# nrf54h20_engb_application register map
Vendor: Nordic Semiconductor; Series: nRF54h; File version: 1
CPU: CM33 r0p4, little endian, MPU, FPU, 3 interrupt priority bits, 480 interrupts, 8 SAU regions
Registers are 32-bit, read-write, reset 0x0 unless marked. A register's access mark holds for its fields unless they carry their own. Offsets are from the block's base; [hi:lo] are bit positions; lines under a group give offsets from that group; {n}, {i} and the like mark numbered series; 'fields as' and 'values as' point back to an identical list.

## GLOBAL_I3CCORE120_NS (part 2 of 2) — I3CCORE 0
Base 0x2FBE0000
Same registers: GLOBAL_I3CCORE121_NS 0x2FBE1000
0x900 DMA group — Unspecified
  0x00 CH0 group — Unspecified
    0x00 SAR0 — This register contains the source address of the DMA transfer.
      [31:0] SAR — Current Source Address of DMA transfer.
    0x08 DAR0 — This register contains the destination address of the DMA transfer.
      [31:0] DAR — Current Destination address of DMA transfer.
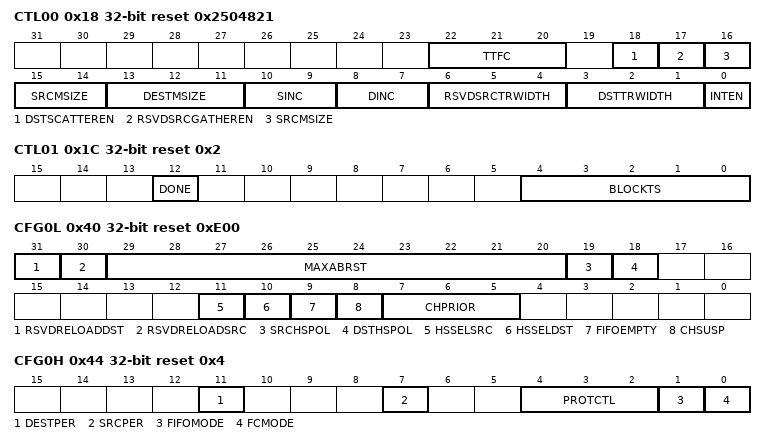
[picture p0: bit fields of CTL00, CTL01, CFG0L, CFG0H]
    0x18 CTL00 reset 0x2504821 — This register contains fields that control the DMA transfer.
      [22:20] TTFC — Transfer Type and Flow Control.
        {v}=TT_FC_{v} (Unspecified) (v=0..7)
      [18] DSTSCATTEREN — Destination scatter enable.
        0=DST_SCATTER_DISABLE (Unspecified); 1=DST_SCATTER_ENABLE (Unspecified)
      [17] RSVDSRCGATHEREN ro — Reserved field - read-only
      [16:14] SRCMSIZE — Source Burst Transaction Length.
        {v}=SRC_MSIZE_{v} (Unspecified) (v=0..7)
      [13:11] DESTMSIZE — Destination Burst Transaction Length.
        {v}=DEST_MSIZE_{v} (Unspecified) (v=0..7)
      [10:9] SINC — Source Address Increment.
        {v}=Unspecified (v=0..3)
      [8:7] DINC — Destination Address Increment.
        {v}=Unspecified (v=0..3)
      [6:4] RSVDSRCTRWIDTH ro — Reserved field - read-only
      [3:1] DSTTRWIDTH — Destination Transfer Width.
        {v}=DST_TR_WIDTH_{v} (Unspecified) (v=0..7)
      [0] INTEN — Interrupt Enable Bit.
        0=INTERRUPT_DISABLE (Unspecified); 1=INTERRUPT_ENABLE (Unspecified)
    0x1C CTL01 reset 0x2 — This register contains fields that control the DMA transfer.
      [12] DONE — Done bit.
        0=DISABLED (Unspecified); 1=ENABLED (Unspecified)
      [4:0] BLOCKTS — Block Transfer Size.
    0x40 CFG0L reset 0xE00 — This register contains fields that configure the DMA transfer.
      [31] RSVDRELOADDST ro — Reserved field- read-only
      [30] RSVDRELOADSRC ro — Reserved field - read-only
      [29:20] MAXABRST — Maximum AMBA Burst Length.
      [19] SRCHSPOL — Source Handshaking Interface Polarity.
        0=ACTIVE_HIGH (Unspecified); 1=ACTIVE_LOW (Unspecified)
      [18] DSTHSPOL — Destination Handshaking Interface Polarity.
        0=ACTIVE_HIGH (Unspecified); 1=ACTIVE_LOW (Unspecified)
      [11] HSSELSRC — Source Software or Hardware Handshaking Select.
        0=HARDWARE_HS (Unspecified); 1=SOFTWARE_HS (Unspecified)
      [10] HSSELDST — Destination Software or Hardware Handshaking Select.
        0=HARDWARE_HS (Unspecified); 1=SOFTWARE_HS (Unspecified)
      [9] FIFOEMPTY ro — Channel FIFO status.
        0=NOT_EMPTY (Unspecified); 1=EMPTY (Unspecified)
      [8] CHSUSP — Channel Suspend.
        0=NOT_SUSPENDED (Unspecified); 1=SUSPENDED (Unspecified)
      [7:5] CHPRIOR — Channel Priority.
        {v}=CH_PRIOR_{v} (Unspecified) (v=0..7)
    0x44 CFG0H reset 0x4 — This register contains fields that configure the DMA transfer.
      [11] DESTPER — Destination hardware interface.
      [7] SRCPER — Source Hardware Interface.
      [4:2] PROTCTL — Protection Control bits used to drive the AHB HPROT[3:1] bus.
      [1] FIFOMODE — FIFO Mode Select.
        0=FIFO_MODE_0 (Unspecified); 1=FIFO_MODE_1 (Unspecified)
      [0] FCMODE — Flow Control Mode.
        0=Unspecified; 1=Unspecified
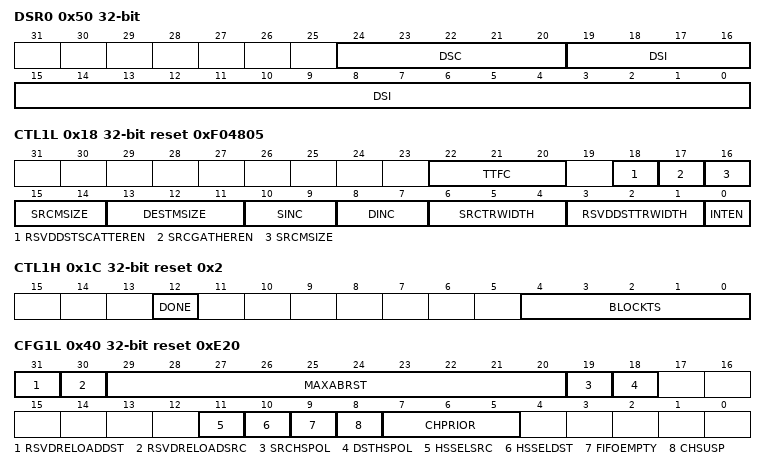
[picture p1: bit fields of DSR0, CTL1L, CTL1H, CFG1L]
    0x50 DSR0 — Destination Scatter register.
      [24:20] DSC — Destination Scatter Count.
      [19:0] DSI — Destination Scatter Interval.
  0x58 CH1 group — Unspecified
    0x00 SAR1 — This register contains the source address of the DMA transfer.
      [31:0] SAR — Current Source Address of DMA transfer.
    0x08 DAR1 — This register contains the destination address of the DMA transfer.
      [31:0] DAR — Current Destination address of DMA transfer.
    0x18 CTL1L reset 0xF04805 — This register contains fields that control the DMA transfer.
      [22:20] TTFC — Transfer Type and Flow Control.
        {v}=TT_FC_{v} (Unspecified) (v=0..7)
      [18] RSVDDSTSCATTEREN ro — Reserved field - read-only
      [17] SRCGATHEREN — Source gather enable.
        0=SRC_GATHER_DISABLE (Unspecified); 1=SRC_GATHER_ENABLE (Unspecified)
      [16:14] SRCMSIZE — Source Burst Transaction Length.
        {v}=SRC_MSIZE_{v} (Unspecified) (v=0..7)
      [13:11] DESTMSIZE — Destination Burst Transaction Length.
        {v}=DEST_MSIZE_{v} (Unspecified) (v=0..7)
      [10:9] SINC — Source Address Increment.
        {v}=Unspecified (v=0..3)
      [8:7] DINC — Destination Address Increment.
        {v}=Unspecified (v=0..3)
      [6:4] SRCTRWIDTH — Source Transfer Width.
        {v}=SRC_TR_WIDTH_{v} (Unspecified) (v=0..7)
      [3:1] RSVDDSTTRWIDTH ro — Reserved field - read-only
      [0] INTEN — Interrupt Enable Bit.
        values as DMA.CH0.CTL00.INTEN
    0x1C CTL1H reset 0x2 — This register contains fields that control the DMA transfer.
      fields as DMA.CH0.CTL01
    0x40 CFG1L reset 0xE20 — This register contains fields that configure the DMA transfer.
      fields as DMA.CH0.CFG0L
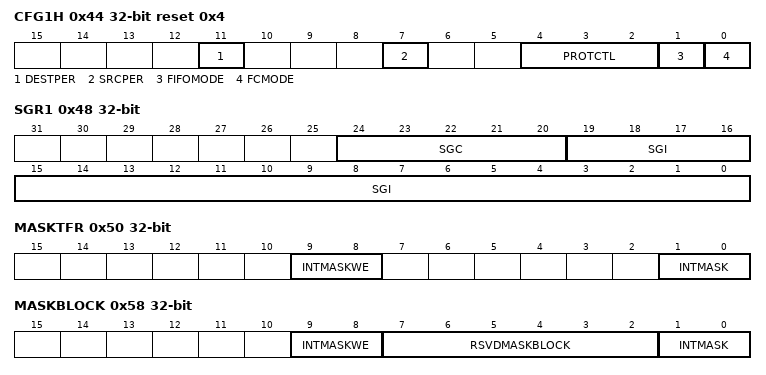
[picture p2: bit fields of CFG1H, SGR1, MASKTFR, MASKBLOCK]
    0x44 CFG1H reset 0x4 — This register contains fields that configure the DMA transfer.
      fields as DMA.CH0.CFG0H
    0x48 SGR1 — Source Gather register
      [24:20] SGC — Source Gather Count.
      [19:0] SGI — Source Gather Interval.
  0x2C0 INT group — Unspecified
    0x00 RAWTFR — Interrupt events are stored in this Raw Interrupt Status register before masking.
      [1:0] RAW — Raw Status for IntTfr Interrupt
        0=INACTIVE (Unspecified); 1=ACTIVE (Unspecified)
    0x08 RAWBLOCK — Interrupt events are stored in this Raw Interrupt Status register before masking.
      [1:0] RAW — Raw Status for IntBlock Interrupt
        0=INACTIVE (Unspecified); 1=ACTIVE (Unspecified)
    0x10 RAWSRCTRAN — Interrupt events are stored in this Raw Interrupt Status register before masking.
      [1:0] RAW — Raw Status for IntSrcTran Interrupt
        0=INACTIVE (Unspecified); 1=ACTIVE (Unspecified)
    0x18 RAWDSTTRAN — Interrupt events are stored in this Raw Interrupt Status register before masking.
      [1:0] RAW — Raw Status for IntDstTran Interrupt
        0=INACTIVE (Unspecified); 1=ACTIVE (Unspecified)
    0x20 RAWERR — Interrupt events are stored in this Raw Interrupt Status register before masking.
      [1:0] RAW — Raw Status for IntErr Interrupt
        0=INACTIVE (Unspecified); 1=ACTIVE (Unspecified)
    0x28 STATUSTFR — Channel DMA Transfer complete interrupt event from all channels is stored in this Interrupt Status register after masking.
      [1:0] STATUS ro — Status for IntTfr Interrupt
        0=INACTIVE (Unspecified); 1=ACTIVE (Unspecified)
    0x30 STATUSBLOCK — Channel Block complete interrupt event from all channels is stored in this Interrupt Status register after masking.
      [1:0] STATUS ro — Status for IntBlock Interrupt
        0=INACTIVE (Unspecified); 1=ACTIVE (Unspecified)
    0x38 STATUSSRCTRAN — Channel Source Transaction complete interrupt event from all channels is stored in this Interrupt Status register after masking.
      [1:0] STATUS ro — Status for IntSrcTran Interrupt
        0=INACTIVE (Unspecified); 1=ACTIVE (Unspecified)
    0x40 STATUSDSTTRAN — Channel destination transaction complete interrupt event from all channels is stored in this Interrupt Status register after masking.
      [1:0] STATUS ro — Status for IntDstTran Interrupt
        0=INACTIVE (Unspecified); 1=ACTIVE (Unspecified)
    0x48 STATUSERR — Channel Error interrupt event from all channels is stored in this Interrupt Status register after masking.
      [1:0] STATUS ro — Status for IntErr Interrupt
        0=INACTIVE (Unspecified); 1=ACTIVE (Unspecified)
    0x50 MASKTFR — The contents of the Raw Status register RawTfr is masked with the contents of the Mask register MaskTfr.
      [9:8] INTMASKWE wo — Interrupt Mask Write Enable
        0=DISABLED (Unspecified); 1=ENABLED (Unspecified)
      [1:0] INTMASK — Mask for IntTfr Interrupt
        0=MASK (Unspecified); 1=UNMASK (Unspecified)
    0x58 MASKBLOCK — The contents of the Raw Status register RawBlock is masked with the contents of the Mask register MaskBlock.
      [9:8] INTMASKWE wo — Interrupt Mask Write Enable
        0=DISABLED (Unspecified); 1=ENABLED (Unspecified)
      [7:2] RSVDMASKBLOCK ro — Reserved field- read-only
      [1:0] INTMASK — Mask for IntBlock Interrupt
        0=MASK (Unspecified); 1=UNMASK (Unspecified)
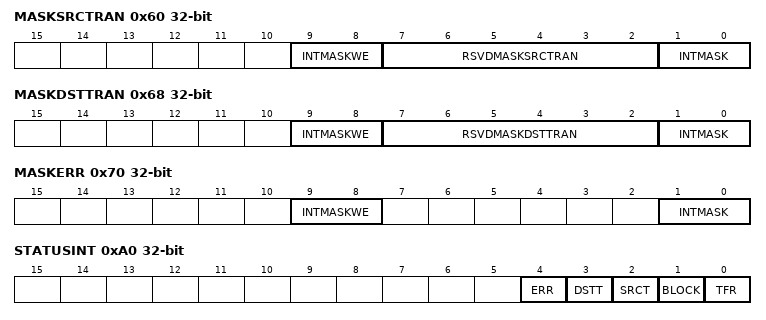
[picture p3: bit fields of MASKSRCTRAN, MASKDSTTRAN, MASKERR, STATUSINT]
    0x60 MASKSRCTRAN — The contents of the Raw Status register RawSrcTran is masked with the contents of the Mask register MaskSrcTran.
      [9:8] INTMASKWE wo — Interrupt Mask Write Enable
        0=DISABLED (Unspecified); 1=ENABLED (Unspecified)
      [7:2] RSVDMASKSRCTRAN ro — Reserved field- read-only
      [1:0] INTMASK — Mask for IntSrcTran Interrupt
        0=MASK (Unspecified); 1=UNMASK (Unspecified)
    0x68 MASKDSTTRAN — The contents of the Raw Status register RawDstTran is masked with the contents of the Mask register MaskDstTran.
      [9:8] INTMASKWE wo — Interrupt Mask Write Enable
        0=DISABLED (Unspecified); 1=ENABLED (Unspecified)
      [7:2] RSVDMASKDSTTRAN ro — Reserved field - read-only
      [1:0] INTMASK — Mask for IntDstTran Interrupt
        0=MASK (Unspecified); 1=UNMASK (Unspecified)
    0x70 MASKERR — The contents of the Raw Status register RawErr is masked with the contents of the Mask register MaskErr.
      [9:8] INTMASKWE wo — Interrupt Mask Write Enable
        0=DISABLED (Unspecified); 1=ENABLED (Unspecified)
      [1:0] INTMASK — Mask for IntErr Interrupt
        0=MASK (Unspecified); 1=UNMASK (Unspecified)
    0x78 CLEARTFR — Each bit in the RawTfr and StatusTfr is cleared on the same cycle by writing a 1 to the corresponding location in the this registers.
      [1:0] CLEAR wo — Clear for IntTfr Interrupt
        0=NOT_CLEAR (Unspecified); 1=CLEAR (Unspecified)
    0x80 CLEARBLOCK — Each bit in the RawBlock and StatusBlock is cleared on the same cycle by writing a 1 to the corresponding location in the this registers.
      [1:0] CLEAR wo — Clear for IntBlock Interrupt
    0x88 CLEARSRCTRAN — Each bit in the RawSrcTran and StatusSrcTran is cleared on the same cycle by writing a 1 to the corresponding location in the this registers.
      [1:0] CLEAR wo — Clear for IntSrcTran Interrupt
        0=NOT_CLEAR (Unspecified); 1=CLEAR (Unspecified)
    0x90 CLEARDSTTRAN — Each bit in the RawDstTran and StatusDstTran is cleared on the same cycle by writing a 1 to the corresponding location in the this registers.
      [1:0] CLEAR wo — Clear for IntDstTran Interrupt
        0=NOT_CLEAR (Unspecified); 1=CLEAR (Unspecified)
    0x98 CLEARERR — Each bit in the RawErr and StatusErr is cleared on the same cycle by writing a 1 to the corresponding location in the this registers.
      [1:0] CLEAR wo — Clear for IntErr Interrupt
        0=NOT_CLEAR (Unspecified); 1=CLEAR (Unspecified)
    0xA0 STATUSINT — The contents of each of the five Status registers StatusTfr, StatusBlock, StatusSrcTran, StatusDstTran, StatusErr is ORed to produce a single bit for each interrupt type in the Combined Status register (StatusInt).
      [all] fields
        0=INACTIVE (Unspecified); 1=ACTIVE (Unspecified)
      [4] ERR ro — OR of the contents of StatusErr
      [3] DSTT ro — OR of the contents of StatusDstTran
      [2] SRCT ro — OR of the contents of StatusSrcTran
      [1] BLOCK ro — OR of the contents of StatusBlock register
      [0] TFR ro — OR of the contents of StatusTfr register
  0x368 SWHANDSHAKE group — Unspecified
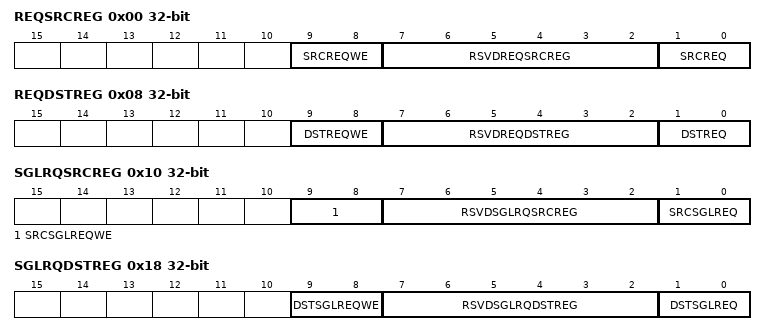
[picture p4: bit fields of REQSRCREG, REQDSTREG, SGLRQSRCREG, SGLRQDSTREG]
    0x00 REQSRCREG — A bit is assigned for each channel in this register.
      [9:8] SRCREQWE wo — Source Software Transaction Request write enable
        0=DISABLED (Unspecified); 1=ENABLED (Unspecified)
      [7:2] RSVDREQSRCREG ro — Reserved field - read-only
      [1:0] SRCREQ — Source Software Transaction Request
        0=INACTIVE (Unspecified); 1=ACTIVE (Unspecified)
    0x08 REQDSTREG — A bit is assigned for each channel in this register.
      [9:8] DSTREQWE wo — Destination Software Transaction Request write enable
        0=DISABLED (Unspecified); 1=ENABLED (Unspecified)
      [7:2] RSVDREQDSTREG ro — Reserved field - read-only
      [1:0] DSTREQ — Destination Software Transaction Request
        0=INACTIVE (Unspecified); 1=ACTIVE (Unspecified)
    0x10 SGLRQSRCREG — A bit is assigned for each channel in this register.
      [9:8] SRCSGLREQWE wo — Source Single Transaction Request write enable
        0=DISABLED (Unspecified); 1=ENABLED (Unspecified)
      [7:2] RSVDSGLRQSRCREG ro — Reserved field - read-only
      [1:0] SRCSGLREQ — Source Single Transaction Request
        0=INACTIVE (Unspecified); 1=ACTIVE (Unspecified)
    0x18 SGLRQDSTREG — A bit is assigned for each channel in this register.
      [9:8] DSTSGLREQWE wo — Destination Single Transaction Request write enable
        0=DISABLED (Unspecified); 1=ENABLED (Unspecified)
      [7:2] RSVDSGLRQDSTREG ro — Reserved field - read-only
      [1:0] DSTSGLREQ — Destination Single Transaction Request
        0=INACTIVE (Unspecified); 1=ACTIVE (Unspecified)
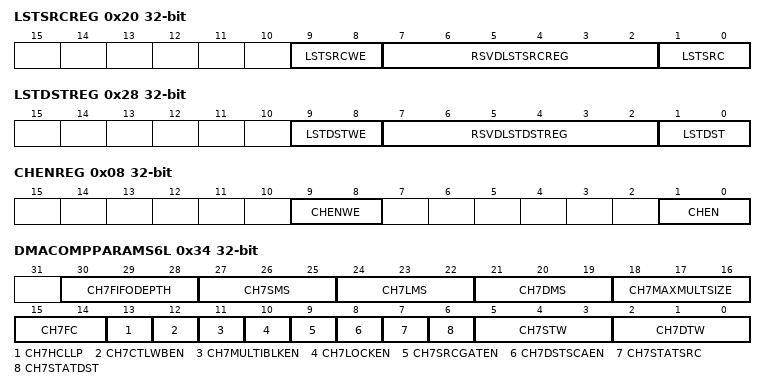
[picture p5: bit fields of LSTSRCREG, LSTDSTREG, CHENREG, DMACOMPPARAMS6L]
    0x20 LSTSRCREG — A bit is assigned for each channel in this register.
      [9:8] LSTSRCWE wo — Source Last Transaction Request write enable
        0=DISABLED (Unspecified); 1=ENABLED (Unspecified)
      [7:2] RSVDLSTSRCREG ro — Reserved field- read-only
      [1:0] LSTSRC — Source Last Transaction Request register
        0=NOT_LAST (Unspecified); 1=LAST (Unspecified)
    0x28 LSTDSTREG — A bit is assigned for each channel in this register.
      [9:8] LSTDSTWE wo — Source Last Transaction Request write enable
        0=DISABLED (Unspecified); 1=ENABLED (Unspecified)
      [7:2] RSVDLSTDSTREG ro — Reserved field - read-only
      [1:0] LSTDST — Destination Last Transaction Request
        0=NOT_LAST (Unspecified); 1=LAST (Unspecified)
  0x398 MISC group — Unspecified
    0x00 DMACFGREG — This register is used to enable the DW_ahb_dmac, which must be done before any channel activity can begin.
      [0] DMAEN — DW_ahb_dmac Enable bit.
        0=DISABLED (Unspecified); 1=ENABLED (Unspecified)
    0x08 CHENREG — This is the DW_ahb_dmac Channel Enable Register.
      [9:8] CHENWE wo — Channel enable register
      [1:0] CHEN — Channel Enable.
        0=DISABLED (Unspecified); 1=ENABLED (Unspecified)
    0x10 DMAIDREG — This is the DW_ahb_dmac ID register, which is a read-only register that reads back the coreConsultant-configured hardcoded ID number, DMAH_ID_NUM.
      [31:0] DMAID ro — Hardcoded DW_ahb_dmac peripheral ID.
    0x18 DMATESTREG — This register is used to put the AHB slave interface into test mode, during which the readback value of the writable registers match the value written, assuming the DW_ahb_dmac configuration has not optimized the same registers.
      [0] TESTSLVIF — DMA Test register
        0=NORMAL_MODE (Unspecified); 1=TEST_MODE (Unspecified)
    0x20 DMALPTIMEOUTREG reset 0x8 — This register holds the timeout value of Low Power Counter.
      [3:0] DMALPTIMEOUT — This field holds timeout value of low power counter register.
    0x34 DMACOMPPARAMS6L — DMA_COMP_PARAMS_6L is a constant read-only register that contains encoded information about the component parameter settings for Channel 7.
      [30:28] CH7FIFODEPTH ro — The value of this register is derived from the DMAH_CH7_FIFO_DEPTH coreConsultant parameter.
        0=FIFO_DEPTH_8 (Unspecified); 1=FIFO_DEPTH_16 (Unspecified); 2=FIFO_DEPTH_32 (Unspecified); 3=FIFO_DEPTH_64 (Unspecified); 4=FIFO_DEPTH_128 (Unspecified); 5=FIFO_DEPTH_256 (Unspecified)
      [27:25] CH7SMS ro — The value of this register is derived from the DMAH_CH7_SMS coreConsultant parameter.
        {v}=MASTER_{v+1} (Unspecified) (v=0..3); 4=PROGRAMMABLE (Unspecified)
      [24:22] CH7LMS ro — The value of this register is derived from the DMAH_CH7_LMS coreConsultant parameter.
        values as CH7SMS
      [21:19] CH7DMS ro — The value of this register is derived from the DMAH_CH7_DMS coreConsultant parameter.
        values as CH7SMS
      [18:16] CH7MAXMULTSIZE ro — The value of this register is derived from the DMAH_CH7_MULT_SIZE coreConsultant parameter.
        0=MAX_MULT_SIZE_4 (Unspecified); 1=MAX_MULT_SIZE_8 (Unspecified); 2=MAX_MULT_SIZE_16 (Unspecified); 3=MAX_MULT_SIZE_32 (Unspecified); 4=MAX_MULT_SIZE_64 (Unspecified); 5=MAX_MULT_SIZE_128 (Unspecified); 6=MAX_MULT_SIZE_256 (Unspecified)
      [15:14] CH7FC ro — The value of this register is derived from the DMAH_CH7_FC coreConsultant parameter.
        0=FC_DMA (Unspecified); 1=FC_SRC (Unspecified); 2=FC_DST (Unspecified); 3=FC_ANY (Unspecified)
      [13] CH7HCLLP ro — The value of this register is derived from the DMAH_CH7_HC_LLP coreConsultant parameter.
        0=PROGRAMMABLE (Unspecified); 1=HARDCODED (Unspecified)
      [12] CH7CTLWBEN ro — The value of this register is derived from the DMAH_CH7_CTL_WB_EN coreConsultant parameter.
        0=FALSE (Unspecified); 1=TRUE (Unspecified)
      [11] CH7MULTIBLKEN ro — The value of this register is derived from the DMAH_CH7_MULTI_BLK_EN coreConsultant parameter.
        0=FALSE (Unspecified); 1=TRUE (Unspecified)
      [10] CH7LOCKEN ro — The value of this register is derived from the DMAH_CH7_LOCK_EN coreConsultant parameter.
        0=FALSE (Unspecified); 1=TRUE (Unspecified)
      [9] CH7SRCGATEN ro — The value of this register is derived from the DMAH_CH7_SRC_GAT_EN coreConsultant parameter.
        0=FALSE (Unspecified); 1=TRUE (Unspecified)
      [8] CH7DSTSCAEN ro — The value of this register is derived from the DMAH_CH7_DST_SCA_EN coreConsultant parameter.
        0=FALSE (Unspecified); 1=TRUE (Unspecified)
      [7] CH7STATSRC ro — The value of this register is derived from the DMAH_CH7_STAT_SRC coreConsultant parameter.
        0=FALSE (Unspecified); 1=TRUE (Unspecified)
      [6] CH7STATDST ro — The value of this register is derived from the DMAH_CH7_STAT_DST coreConsultant parameter.
        0=FALSE (Unspecified); 1=TRUE (Unspecified)
      [5:3] CH7STW ro — The value of this register is derived from the DMAH_CH7_STW coreConsultant parameter.
        0=NO_HARDCODE (Unspecified); 1=STW_8 (Unspecified); 2=STW_16 (Unspecified); 3=STW_32 (Unspecified); 4=STW_64 (Unspecified); 5=STW_128 (Unspecified); 6=STW_256 (Unspecified)
      [2:0] CH7DTW ro — The value of this register is derived from the DMAH_CH7_DTW coreConsultant parameter.
        0=NO_HARDCODE (Unspecified); 1=DTW_8 (Unspecified); 2=DTW_16 (Unspecified); 3=DTW_32 (Unspecified); 4=DTW_64 (Unspecified); 5=DTW_128 (Unspecified); 6=DTW_256 (Unspecified)
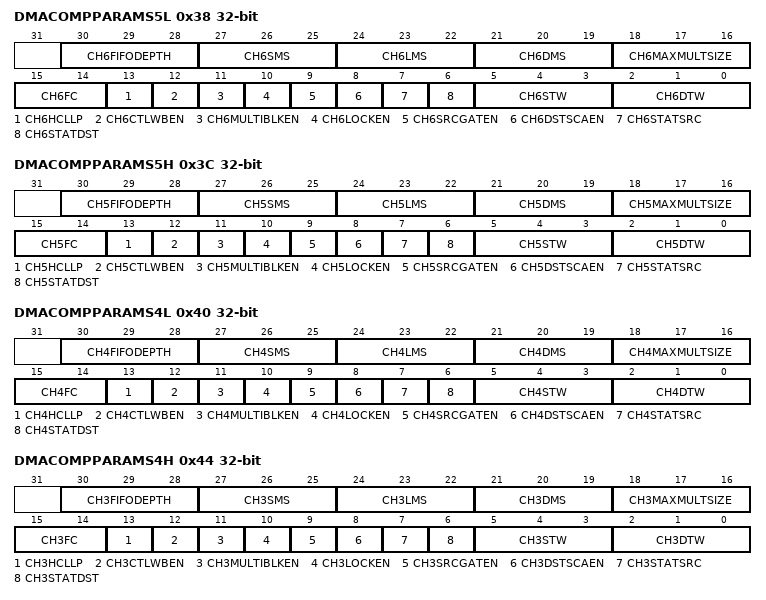
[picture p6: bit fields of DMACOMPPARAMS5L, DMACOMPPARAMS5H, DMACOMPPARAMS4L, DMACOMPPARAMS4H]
    0x38 DMACOMPPARAMS5L — DMA_COMP_PARAMS_5 is a constant read-only register that contains encoded information about the component parameter settings for Channel 5 and Channel 6.
      [30:28] CH6FIFODEPTH ro — The value of this register is derived from the DMAH_CH6_FIFO_DEPTH coreConsultant parameter.
        0=IFO_DEPTH_8 (Unspecified); 1=FIFO_DEPTH_16 (Unspecified); 2=FIFO_DEPTH_32 (Unspecified); 3=FIFO_DEPTH_64 (Unspecified); 4=FIFO_DEPTH_128 (Unspecified); 5=FIFO_DEPTH_256 (Unspecified)
      [27:25] CH6SMS ro — The value of this register is derived from the DMAH_CH6_SMS coreConsultant parameter.
        values as DMA.MISC.DMACOMPPARAMS6L.CH7SMS
      [24:22] CH6LMS ro — The value of this register is derived from the DMAH_CH6_LMS coreConsultant parameter.
        values as DMA.MISC.DMACOMPPARAMS6L.CH7SMS
      [21:19] CH6DMS ro — The value of this register is derived from the DMAH_CH6_DMS coreConsultant parameter.
        values as DMA.MISC.DMACOMPPARAMS6L.CH7SMS
      [18:16] CH6MAXMULTSIZE ro — The value of this register is derived from the DMAH_CH6_MULT_SIZE coreConsultant parameter.
        values as DMA.MISC.DMACOMPPARAMS6L.CH7MAXMULTSIZE
      [15:14] CH6FC ro — The value of this register is derived from the DMAH_CH6_FC coreConsultant parameter.
        values as DMA.MISC.DMACOMPPARAMS6L.CH7FC
      [13] CH6HCLLP ro — The value of this register is derived from the DMAH_CH6_HC_LLP coreConsultant parameter.
        0=PROGRAMMABLE (Unspecified); 1=HARDCODED (Unspecified)
      [12] CH6CTLWBEN ro — The value of this register is derived from the DMAH_CH6_CTL_WB_EN coreConsultant parameter.
        0=FALSE (Unspecified); 1=TRUE (Unspecified)
      [11] CH6MULTIBLKEN ro — The value of this register is derived from the DMAH_CH6_MULTI_BLK_EN coreConsultant parameter.
        0=FALSE (Unspecified); 1=TRUE (Unspecified)
      [10] CH6LOCKEN ro — The value of this register is derived from the DMAH_CH6_LOCK_EN coreConsultant parameter.
        0=FALSE (Unspecified); 1=TRUE (Unspecified)
      [9] CH6SRCGATEN ro — The value of this register is derived from the CH6_SRC_GAT_EN coreConsultant parameter.
        0=FALSE (Unspecified); 1=TRUE (Unspecified)
      [8] CH6DSTSCAEN ro — The value of this register is derived from the DMAH_CH6_DST_SCA_EN coreConsultant parameter.
        0=FALSE (Unspecified); 1=TRUE (Unspecified)
      [7] CH6STATSRC ro — The value of this register is derived from the DMAH_CH6_STAT_SRC coreConsultant parameter.
        0=FALSE (Unspecified); 1=TRUE (Unspecified)
      [6] CH6STATDST ro — The value of this register is derived from the DMAH_CH6_STAT_DST coreConsultant parameter.
        0=FALSE (Unspecified); 1=TRUE (Unspecified)
      [5:3] CH6STW ro — The value of this register is derived from the DMAH_CH6_STW coreConsultant parameter.
        0=TRANS_WIDTH_PROGRAMMABLE (Unspecified); 1=TRANS_WIDTH_8 (Unspecified); 2=TRANS_WIDTH_16 (Unspecified); 3=TRANS_WIDTH_32 (Unspecified); 4=TRANS_WIDTH_64 (Unspecified); 5=TRANS_WIDTH_128 (Unspecified); 6=TRANS_WIDTH_256 (Unspecified)
      [2:0] CH6DTW ro — The value of this register is derived from the DMAH_CH6_DTW coreConsultant parameter.
        values as CH6STW
    0x3C DMACOMPPARAMS5H — DMA_COMP_PARAMS_5 is a constant read-only register that contains encoded information about the component parameter settings for Channel 5 and Channel 6.
      [30:28] CH5FIFODEPTH ro — The value of this register is derived from the DMAH_CH5_FIFO_DEPTH coreConsultant parameter.
        values as DMA.MISC.DMACOMPPARAMS6L.CH7FIFODEPTH
      [27:25] CH5SMS ro — The value of this register is derived from the DMAH_CH5_SMS coreConsultant parameter.
        values as DMA.MISC.DMACOMPPARAMS6L.CH7SMS
      [24:22] CH5LMS ro — The value of this register is derived from the DMAH_CH5_LMS coreConsultant parameter.
        values as DMA.MISC.DMACOMPPARAMS6L.CH7SMS
      [21:19] CH5DMS ro — The value of this register is derived from the DMAH_CH5_DMS coreConsultant parameter.
        values as DMA.MISC.DMACOMPPARAMS6L.CH7SMS
      [18:16] CH5MAXMULTSIZE ro — The value of this register is derived from the DMAH_CH5_MULT_SIZE coreConsultant parameter.
        values as DMA.MISC.DMACOMPPARAMS6L.CH7MAXMULTSIZE
      [15:14] CH5FC ro — The value of this register is derived from the DMAH_CH5_FC coreConsultant parameter.
        values as DMA.MISC.DMACOMPPARAMS6L.CH7FC
      [13] CH5HCLLP ro — The value of this register is derived from the DMAH_CH5_HC_LLP coreConsultant parameter.
        0=PROGRAMMABLE (Unspecified); 1=HARDCODED (Unspecified)
      [12] CH5CTLWBEN ro — The value of this register is derived from the DMAH_CH5_CTL_WB_EN coreConsultant parameter.
        0=FALSE (Unspecified); 1=TRUE (Unspecified)
      [11] CH5MULTIBLKEN ro — The value of this register is derived from the DMAH_CH5_MULTI_BLK_EN coreConsultant parameter.
        0=FALSE (Unspecified); 1=TRUE (Unspecified)
      [10] CH5LOCKEN ro — The value of this register is derived from the DMAH_CH5_LOCK_EN coreConsultant parameter.
        0=FALSE (Unspecified); 1=TRUE (Unspecified)
      [9] CH5SRCGATEN ro — The value of this register is derived from the DMAH_CH5_SRC_GAT_EN coreConsultant parameter.
        0=FALSE (Unspecified); 1=TRUE (Unspecified)
      [8] CH5DSTSCAEN ro — The value of this register is derived from the DMAH_CH5_DST_SCA_EN coreConsultant parameter.
        0=FALSE (Unspecified); 1=TRUE (Unspecified)
      [7] CH5STATSRC ro — The value of this register is derived from the DMAH_CH5_STAT_SRC coreConsultant parameter.
        0=FALSE (Unspecified); 1=TRUE (Unspecified)
      [6] CH5STATDST ro — The value of this register is derived from the DMAH_CH5_STAT_DST coreConsultant parameter.
        0=FALSE (Unspecified); 1=TRUE (Unspecified)
      [5:3] CH5STW ro — The value of this register is derived from the DMAH_CH5_STW coreConsultant parameter.
        values as DMA.MISC.DMACOMPPARAMS5L.CH6STW
      [2:0] CH5DTW ro — The value of this register is derived from the DMAH_CH5_DTW coreConsultant parameter.
        values as DMA.MISC.DMACOMPPARAMS5L.CH6STW
    0x40 DMACOMPPARAMS4L — DMA_COMP_PARAMS_4 is a constant read-only register that contains encoded information about the component parameter settings for Channel 3 and Channel 4.
      [30:28] CH4FIFODEPTH ro — The value of this register is derived from the DMAH_CH4_FIFO_DEPTH coreConsultant parameter.
        values as DMA.MISC.DMACOMPPARAMS6L.CH7FIFODEPTH
      [27:25] CH4SMS ro — The value of this register is derived from the DMAH_CH4_SMS coreConsultant parameter.
        values as DMA.MISC.DMACOMPPARAMS6L.CH7SMS
      [24:22] CH4LMS ro — The value of this register is derived from the DMAH_CH4_LMS coreConsultant parameter.
        values as DMA.MISC.DMACOMPPARAMS6L.CH7SMS
      [21:19] CH4DMS ro — The value of this register is derived from the DMAH_CH4_DMS coreConsultant parameter.
        values as DMA.MISC.DMACOMPPARAMS6L.CH7SMS
      [18:16] CH4MAXMULTSIZE ro — The value of this register is derived from the DMAH_CH4_MULT_SIZE coreConsultant parameter.
        values as DMA.MISC.DMACOMPPARAMS6L.CH7MAXMULTSIZE
      [15:14] CH4FC ro — The value of this register is derived from the DMAH_CH4_FC coreConsultant parameter.
        values as DMA.MISC.DMACOMPPARAMS6L.CH7FC
      [13] CH4HCLLP ro — The value of this register is derived from the DMAH_CH4_HC_LLP coreConsultant parameter.
        0=PROGRAMMABLE (Unspecified); 1=HARDCODED (Unspecified)
      [12] CH4CTLWBEN ro — The value of this register is derived from the DMAH_CH4_CTL_WB_EN coreConsultant parameter.
        0=FALSE (Unspecified); 1=TRUE (Unspecified)
      [11] CH4MULTIBLKEN ro — The value of this register is derived from the DMAH_CH4_MULTI_BLK_EN coreConsultant parameter.
        0=FALSE (Unspecified); 1=TRUE (Unspecified)
      [10] CH4LOCKEN ro — The value of this register is derived from the DMAH_CH4_LOCK_EN coreConsultant parameter.
        0=FALSE (Unspecified); 1=TRUE (Unspecified)
      [9] CH4SRCGATEN ro — The value of this register is derived from the DMAH_CH4_SRC_GAT_EN coreConsultant parameter.
        0=FALSE (Unspecified); 1=TRUE (Unspecified)
      [8] CH4DSTSCAEN ro — The value of this register is derived from the DMAH_CH4_DST_SCA_EN coreConsultant parameter.
        0=FALSE (Unspecified); 1=TRUE (Unspecified)
      [7] CH4STATSRC ro — The value of this register is derived from the DMAH_CH4_STAT_SRC coreConsultant parameter.
        0=FALSE (Unspecified); 1=TRUE (Unspecified)
      [6] CH4STATDST ro — The value of this register is derived from the DMAH_CH4_STAT_DST coreConsultant parameter.
        0=FALSE (Unspecified); 1=TRUE (Unspecified)
      [5:3] CH4STW ro — The value of this register is derived from the DMAH_CH4_STW coreConsultant parameter.
        values as DMA.MISC.DMACOMPPARAMS5L.CH6STW
      [2:0] CH4DTW ro — The value of this register is derived from the DMAH_CH4_DTW coreConsultant parameter.
        values as DMA.MISC.DMACOMPPARAMS5L.CH6STW
    0x44 DMACOMPPARAMS4H — DMA_COMP_PARAMS_4 is a constant read-only register that contains encoded information about the component parameter settings for Channel 3 and Channel 4.
      [30:28] CH3FIFODEPTH ro — The value of this register is derived from the DMAH_CH3_FIFO_DEPTH coreConsultant parameter.
        values as DMA.MISC.DMACOMPPARAMS6L.CH7FIFODEPTH
      [27:25] CH3SMS ro — The value of this register is derived from the DMAH_CH3_SMS coreConsultant parameter.
        values as DMA.MISC.DMACOMPPARAMS6L.CH7SMS
      [24:22] CH3LMS ro — The value of this register is derived from the DMAH_CH3_LMS coreConsultant parameter.
        values as DMA.MISC.DMACOMPPARAMS6L.CH7SMS
      [21:19] CH3DMS ro — The value of this register is derived from the DMAH_CH3_DMS coreConsultant parameter.
        values as DMA.MISC.DMACOMPPARAMS6L.CH7SMS
      [18:16] CH3MAXMULTSIZE ro — The value of this register is derived from the DMAH_CH3_MULT_SIZE coreConsultant parameter.
        values as DMA.MISC.DMACOMPPARAMS6L.CH7MAXMULTSIZE
      [15:14] CH3FC ro — The value of this register is derived from the DMAH_CH3_FC coreConsultant parameter.
        values as DMA.MISC.DMACOMPPARAMS6L.CH7FC
      [13] CH3HCLLP ro — The value of this register is derived from the DMAH_CH3_HC_LLP coreConsultant parameter.
        0=PROGRAMMABLE (Unspecified); 1=HARDCODED (Unspecified)
      [12] CH3CTLWBEN ro — The value of this register is derived from the DMAH_CH3_CTL_WB_EN coreConsultant parameter.
        0=FALSE (Unspecified); 1=TRUE (Unspecified)
      [11] CH3MULTIBLKEN ro — The value of this register is derived from the DMAH_CH3_MULTI_BLK_EN coreConsultant parameter.
        0=FALSE (Unspecified); 1=TRUE (Unspecified)
      [10] CH3LOCKEN ro — The value of this register is derived from the DMAH_CH3_LOCK_EN coreConsultant parameter.
        0=FALSE (Unspecified); 1=TRUE (Unspecified)
      [9] CH3SRCGATEN ro — The value of this register is derived from the DMAH_CH3_SRC_GAT_EN coreConsultant parameter.
        0=FALSE (Unspecified); 1=TRUE (Unspecified)
      [8] CH3DSTSCAEN ro — The value of this register is derived from the DMAH_CH3_DST_SCA_EN coreConsultant parameter.
        0=FALSE (Unspecified); 1=TRUE (Unspecified)
      [7] CH3STATSRC ro — The value of this register is derived from the DMAH_CH3_STAT_SRC coreConsultant parameter.
        0=FALSE (Unspecified); 1=TRUE (Unspecified)
      [6] CH3STATDST ro — The value of this register is derived from the DMAH_CH3_STAT_DST coreConsultant parameter.
        0=FALSE (Unspecified); 1=TRUE (Unspecified)
      [5:3] CH3STW ro — The value of this register is derived from the DMAH_CH3_STW coreConsultant parameter.
        values as DMA.MISC.DMACOMPPARAMS5L.CH6STW
      [2:0] CH3DTW ro — The value of this register is derived from the DMAH_CH3_DTW coreConsultant parameter.
        values as DMA.MISC.DMACOMPPARAMS5L.CH6STW
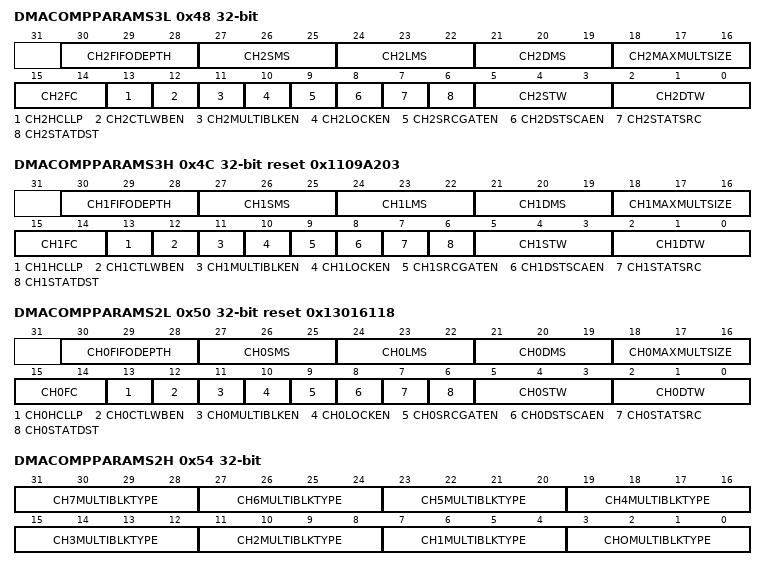
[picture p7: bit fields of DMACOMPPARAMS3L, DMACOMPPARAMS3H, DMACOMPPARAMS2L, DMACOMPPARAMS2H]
    0x48 DMACOMPPARAMS3L — DMA_COMP_PARAMS_3 is a constant read-only register that contains encoded information about the component parameter settings for Channel 1 and Channel 2.
      [30:28] CH2FIFODEPTH ro — The value of this register is derived from the DMAH_CH2_FIFO_DEPTH coreConsultant parameter.
        values as DMA.MISC.DMACOMPPARAMS6L.CH7FIFODEPTH
      [27:25] CH2SMS ro — The value of this register is derived from the DMAH_CH2_SMS coreConsultant parameter.
        {v}=MASTER_{v+1} (Unspecified) (v=0..3); 4=PROGRAMMALE (Unspecified)
      [24:22] CH2LMS ro — The value of this register is derived from the DMAH_CH2_LMS coreConsultant parameter.
        values as CH2SMS
      [21:19] CH2DMS ro — The value of this register is derived from the DMAH_CH2_DMS coreConsultant parameter.
        values as DMA.MISC.DMACOMPPARAMS6L.CH7SMS
      [18:16] CH2MAXMULTSIZE ro — The value of this register is derived from the DMAH_CH2_MULT_SIZE coreConsultant parameter.
        values as DMA.MISC.DMACOMPPARAMS6L.CH7MAXMULTSIZE
      [15:14] CH2FC ro — The value of this register is derived from the DMAH_CH2_FC coreConsultant parameter.
        values as DMA.MISC.DMACOMPPARAMS6L.CH7FC
      [13] CH2HCLLP ro — The value of this register is derived from the DMAH_CH2_HC_LLP coreConsultant parameter.
        0=PROGRAMMABLE (Unspecified); 1=HARDCODED (Unspecified)
      [12] CH2CTLWBEN ro — The value of this register is derived from the DMAH_CH2_CTL_WB_EN coreConsultant parameter.
        0=FALSE (Unspecified); 1=TRUE (Unspecified)
      [11] CH2MULTIBLKEN ro — The value of this register is derived from the DMAH_CH2_MULTI_BLK_EN coreConsultant parameter.
        0=FALSE (Unspecified); 1=TRUE (Unspecified)
      [10] CH2LOCKEN ro — The value of this register is derived from the DMAH_CH2_LOCK_EN coreConsultant parameter.
        0=FALSE (Unspecified); 1=TRUE (Unspecified)
      [9] CH2SRCGATEN ro — The value of this register is derived from the DMAH_CH2_SRC_GAT_EN coreConsultant parameter.
        0=FALSE (Unspecified); 1=TRUE (Unspecified)
      [8] CH2DSTSCAEN ro — The value of this register is derived from the DMAH_CH2_DST_SCA_EN coreConsultant parameter.
        0=FALSE (Unspecified); 1=TRUE (Unspecified)
      [7] CH2STATSRC ro — The value of this register is derived from the DMAH_CH2_STAT_SRC coreConsultant parameter.
        0=FALSE (Unspecified); 1=TRUE (Unspecified)
      [6] CH2STATDST ro — The value of this register is derived from the DMAH_CH2_STAT_DST coreConsultant parameter.
        0=FALSE (Unspecified); 1=TRUE (Unspecified)
      [5:3] CH2STW ro — The value of this register is derived from the DMAH_CH2_STW coreConsultant parameter.
        values as DMA.MISC.DMACOMPPARAMS5L.CH6STW
      [2:0] CH2DTW ro — The value of this register is derived from the DMAH_CH2_DTW coreConsultant parameter.
        values as DMA.MISC.DMACOMPPARAMS5L.CH6STW
    0x4C DMACOMPPARAMS3H reset 0x1109A203 — DMA_COMP_PARAMS_3 is a constant read-only register that contains encoded information about the component parameter settings for Channel 1 and Channel 2.
      [30:28] CH1FIFODEPTH ro — The value of this register is derived from the DMAH_CH1_FIFO_DEPTH coreConsultant parameter.
        values as DMA.MISC.DMACOMPPARAMS6L.CH7FIFODEPTH
      [27:25] CH1SMS ro — The value of this register is derived from the DMAH_CH1_SMS coreConsultant parameter.
        values as DMA.MISC.DMACOMPPARAMS6L.CH7SMS
      [24:22] CH1LMS ro — The value of this register is derived from the DMAH_CH1_LMS coreConsultant parameter.
        values as DMA.MISC.DMACOMPPARAMS6L.CH7SMS
      [21:19] CH1DMS ro — The value of this register is derived from the DMAH_CH1_DMS coreConsultant parameter.
        values as DMA.MISC.DMACOMPPARAMS6L.CH7SMS
      [18:16] CH1MAXMULTSIZE ro — The value of this register is derived from the DMAH_CH1_MULT_SIZE coreConsultant parameter.
        values as DMA.MISC.DMACOMPPARAMS6L.CH7MAXMULTSIZE
      [15:14] CH1FC ro — The value of this register is derived from the DMAH_CH1_FC coreConsultant parameter.
        values as DMA.MISC.DMACOMPPARAMS6L.CH7FC
      [13] CH1HCLLP ro — The value of this register is derived from the DMAH_CH1_HC_LLP coreConsultant parameter.
        0=PROGRAMMABLE (Unspecified); 1=HARDCODED (Unspecified)
      [12] CH1CTLWBEN ro — The value of this register is derived from the DMAH_CH1_CTL_WB_EN coreConsultant parameter.
        0=FALSE (Unspecified); 1=TRUE (Unspecified)
      [11] CH1MULTIBLKEN ro — The value of this register is derived from the DMAH_CH1_MULTI_BLK_EN coreConsultant parameter.
        0=FALSE (Unspecified); 1=TRUE (Unspecified)
      [10] CH1LOCKEN ro — The value of this register is derived from the DMAH_CH1_LOCK_EN coreConsultant parameter.
        0=FALSE (Unspecified); 1=TRUE (Unspecified)
      [9] CH1SRCGATEN ro — The value of this register is derived from the DMAH_CH1_SRC_GAT_EN coreConsultant parameter.
        0=FALSE (Unspecified); 1=TRUE (Unspecified)
      [8] CH1DSTSCAEN ro — The value of this register is derived from the DMAH_CH1_DST_SCA_EN coreConsultant parameter.
        0=FALSE (Unspecified); 1=TRUE (Unspecified)
      [7] CH1STATSRC ro — The value of this register is derived from the DMAH_CH1_STAT_SRC coreConsultant parameter.
        0=FALSE (Unspecified); 1=TRUE (Unspecified)
      [6] CH1STATDST ro — The value of this register is derived from the DMAH_CH1_STAT_DST coreConsultant parameter.
        0=FALSE (Unspecified); 1=TRUE (Unspecified)
      [5:3] CH1STW ro — The value of this register is derived from the DMAH_CH1_STW coreConsultant parameter.
        values as DMA.MISC.DMACOMPPARAMS5L.CH6STW
      [2:0] CH1DTW ro — The value of this register is derived from the DMAH_CH1_DTW coreConsultant parameter.
        values as DMA.MISC.DMACOMPPARAMS5L.CH6STW
    0x50 DMACOMPPARAMS2L reset 0x13016118 — DMA_COMP_PARAMS_2 is a constant read-only register that contains encoded information about the component parameter settings.
      [30:28] CH0FIFODEPTH ro — The value of this register is derived from the DMAH_CH0_FIFO_DEPTH coreConsultant parameter.
        values as DMA.MISC.DMACOMPPARAMS6L.CH7FIFODEPTH
      [27:25] CH0SMS ro — The value of this register is derived from the DMAH_CH0_SMS coreConsultant parameter.
        values as DMA.MISC.DMACOMPPARAMS6L.CH7SMS
      [24:22] CH0LMS ro — The value of this register is derived from the DMAH_CH0_LMS coreConsultant parameter.
        values as DMA.MISC.DMACOMPPARAMS6L.CH7SMS
      [21:19] CH0DMS ro — The value of this register is derived from the DMAH_CH0_DMS coreConsultant parameter.
        values as DMA.MISC.DMACOMPPARAMS6L.CH7SMS
      [18:16] CH0MAXMULTSIZE ro — The value of this register is derived from the DMAH_CH0_MULT_SIZE coreConsultant parameter.
        values as DMA.MISC.DMACOMPPARAMS6L.CH7MAXMULTSIZE
      [15:14] CH0FC ro — The value of this register is derived from the DMAH_CH0_FC coreConsultant parameter.
        values as DMA.MISC.DMACOMPPARAMS6L.CH7FC
      [13] CH0HCLLP ro — The value of this register is derived from the DMAH_CH0_HC_LLP coreConsultant parameter.
        0=PROGRAMMABLE (Unspecified); 1=HARDCODED (Unspecified)
      [12] CH0CTLWBEN ro — The value of this register is derived from the DMAH_CH0_CTL_WB_EN coreConsultant parameter.
        0=FALSE (Unspecified); 1=TRUE (Unspecified)
      [11] CH0MULTIBLKEN ro — The value of this register is derived from the DMAH_CH0_MULTI_BLK_EN coreConsultant parameter.
        0=FALSE (Unspecified); 1=TRUE (Unspecified)
      [10] CH0LOCKEN ro — The value of this register is derived from the DMAH_CH0_LOCK_EN coreConsultant parameter.
        0=FALSE (Unspecified); 1=TRUE (Unspecified)
      [9] CH0SRCGATEN ro — The value of this register is derived from the DMAH_CH0_SRC_GAT_EN coreConsultant parameter.
        0=FALSE (Unspecified); 1=TRUE (Unspecified)
      [8] CH0DSTSCAEN ro — The value of this register is derived from the DMAH_CH0_DST_SCA_EN coreConsultant parameter.
        0=FALSE (Unspecified); 1=TRUE (Unspecified)
      [7] CH0STATSRC ro — The value of this register is derived from the DMAH_CH0_STAT_SRC coreConsultant parameter.
        0=FALSE (Unspecified); 1=TRUE (Unspecified)
      [6] CH0STATDST ro — The value of this register is derived from the DMAH_CH0_STAT_DST coreConsultant parameter.
        0=FALSE (Unspecified); 1=TRUE (Unspecified)
      [5:3] CH0STW ro — The value of this register is derived from the DMAH_CH0_STW coreConsultant parameter.
        values as DMA.MISC.DMACOMPPARAMS5L.CH6STW
      [2:0] CH0DTW ro — The value of this register is derived from the DMAH_CH0_DTW coreConsultant parameter.
        values as DMA.MISC.DMACOMPPARAMS5L.CH6STW
    0x54 DMACOMPPARAMS2H — DMA_COMP_PARAMS_2 is a constant read-only register that contains encoded information about the component parameter settings.
      [all] fields
        0=PROGRAMMABLE (Unspecified); 1=CONT_RELOAD (Unspecified); 2=RELOAD_CONT (Unspecified); 3=RELOAD_RELOAD (Unspecified); 4=CONT_LLP (Unspecified); 5=RELOAD_LLP (Unspecified); 6=CNT_LLP (Unspecified); 7=LLP_RELOAD (Unspecified); 8=LLP_LLP (Unspecified)
      [4n+3:4n] CH{n}MULTIBLKTYPE ro (n=1..7) — The values of these bit fields are derived from the DMAH_CH{n}_MULTI_BLK_TYPE coreConsultant parameter.
      [3:0] CHOMULTIBLKTYPE ro — The values of these bit fields are derived from the DMAH_CH0_MULTI_BLK_TYPE coreConsultant parameter.
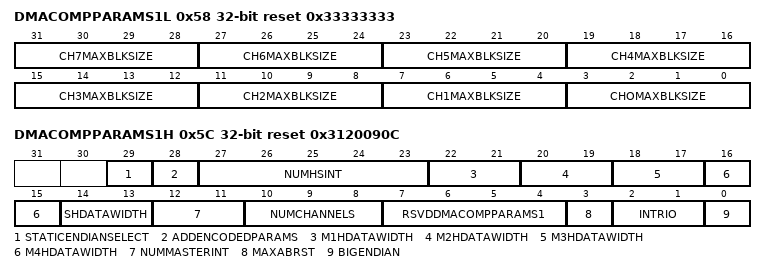
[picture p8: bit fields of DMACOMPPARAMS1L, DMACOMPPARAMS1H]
    0x58 DMACOMPPARAMS1L reset 0x33333333 — DMA_COMP_PARAMS_1 is a constant read-only register that contains encoded information about the component parameter settings.
      [all] fields
        0=MAX_BLOCK_SIZE_3 (Unspecified); 1=MAX_BLOCK_SIZE_7 (Unspecified); 2=MAX_BLOCK_SIZE_15 (Unspecified); 3=MAX_BLOCK_SIZE_31 (Unspecified); 4=MAX_BLOCK_SIZE_63 (Unspecified); 5=MAX_BLOCK_SIZE_127 (Unspecified); 6=MAX_BLOCK_SIZE_255 (Unspecified); 7=MAX_BLOCK_SIZE_511 (Unspecified); 8=MAX_BLOCK_SIZE_1023 (Unspecified); 9=MAX_BLOCK_SIZE_2047 (Unspecified); 10=MAX_BLOCK_SIZE_4095 (Unspecified)
      [4n+3:4n] CH{n}MAXBLKSIZE ro (n=1..7) — The values of these bit fields are derived from the DMAH_CH{n}_MAX_BLK_SIZE coreConsultant parameter.
      [3:0] CHOMAXBLKSIZE ro — The values of these bit fields are derived from the DMAH_CH0_MAX_BLK_SIZE coreConsultant parameter.
    0x5C DMACOMPPARAMS1H reset 0x3120090C — DMA_COMP_PARAMS_1 is a constant read-only register that contains encoded information about the component parameter settings.
      [29] STATICENDIANSELECT ro — The value of this register is derived from the DMAH_STATIC_ENDIAN_SELECT coreConsultant parameter.
      [28] ADDENCODEDPARAMS ro — The value of this register is derived from the DMAH_ADD_ENCODED_PARAMS coreConsultant parameter.
        0=FALSE (Unspecified); 1=TRUE (Unspecified)
      [27:23] NUMHSINT ro — The value of this register is derived from the DMAH_NUM_HS_INT coreConsultant parameter.
        {v}=HS_INTERFACE_{v} (Unspecified) (v=0..9); 10=HS_INTERFACE_a (Unspecified); 11=HS_INTERFACE_b (Unspecified); 12=HS_INTERFACE_c (Unspecified); 13=HS_INTERFACE_d (Unspecified); 14=HS_INTERFACE_e (Unspecified); 15=HS_INTERFACE_f (Unspecified); 16=HS_INTERFACE_10 (Unspecified)
      [24-2n:23-2n] M{n}HDATAWIDTH ro (n=1..4) — The value of this register is derived from the DMAH_M{n}_HDATA_WIDTH coreConsultant parameter.
        0=DATA_BUS_WIDTH_32 (Unspecified); 1=DATA_BUS_WIDTH_64 (Unspecified); 2=DATA_BUS_WIDTH_128 (Unspecified); 3=DATA_BUS_WIDTH_256 (Unspecified)
      [14:13] SHDATAWIDTH ro — The value of this register is derived from the DMAH_S_HDATA_WIDTH coreConsultant parameter.
        values as M1HDATAWIDTH
      [12:11] NUMMASTERINT ro — The value of this register is derived from the DMAH_NUM_MASTER_INT coreConsultant parameter.
        {v}=NUM_MST_INTERFACE_{v+1} (Unspecified) (v=0..3)
      [10:8] NUMCHANNELS ro — The value of this register is derived from the DMAH_NUM_CHANNELS coreConsultant parameter.
        {v}=NUM_CHANNEL_{v+1} (Unspecified) (v=0..7)
      [7:4] RSVDDMACOMPPARAMS1 ro — Reserved field- read-only
      [3] MAXABRST ro — The value of this register is derived from the DMAH_MABRST coreConsultant parameter.
        0=FALSE (Unspecified); 1=TRUE (Unspecified)
      [2:1] INTRIO ro — The value of this register is derived from the DMAH_INTR_IO coreConsultant parameter.
        0=ALL_INT (Unspecified); 1=TYPE_INT (Unspecified); 2=COMBINED_INT (Unspecified)
      [0] BIGENDIAN ro — The value of this register is derived from the DMAH_BIG_ENDIAN coreConsultant parameter.
        0=FALSE (Unspecified); 1=TRUE (Unspecified)
    0x60 DMACOMPSID0 reset 0x44571110 — This is the DW_ahb_dmac Component Version register, which is a read-only register that specifies the component type.
      [31:0] DMACOMPTYPE ro — DMA Component Type Number = `h44571110.
    0x64 DMACOMPSID1 reset 0x3232322A — This is the DW_ahb_dmac Component Version register, which is a read-only register that specifies the version of the packaged component.
      [31:0] DMACOMPVERSION ro — DMA Component Version.
